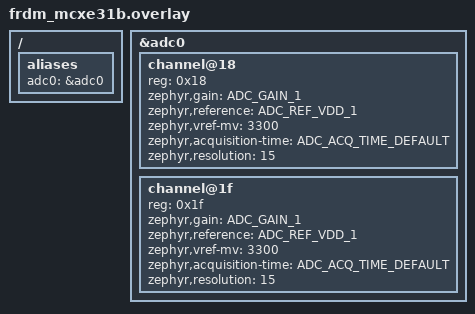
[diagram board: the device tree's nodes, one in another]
/*
 * Copyright 2025 NXP
 *
 * SPDX-License-Identifier: Apache-2.0
 */

#include <zephyr/dt-bindings/adc/adc.h>

/ {
	aliases {
		adc0 = &adc0;
	};
};

&adc0 {
	#address-cells = <1>;
	#size-cells = <0>;

	/* logic channel 24(0x18) => physical channel 48 (Internal 1.2v bandgap) */
	channel@18 {
		reg = <0x18>;
		zephyr,gain = "ADC_GAIN_1";
		zephyr,reference = "ADC_REF_VDD_1";
		zephyr,vref-mv = <3300>;
		zephyr,acquisition-time = <ADC_ACQ_TIME_DEFAULT>;
		zephyr,resolution = <15>;
	};

	/* logic channel 31(0x1F) => physical channel 55 (VREFH 3.3v) */
	channel@1f {
		reg = <0x1f>;
		zephyr,gain = "ADC_GAIN_1";
		zephyr,reference = "ADC_REF_VDD_1";
		zephyr,vref-mv = <3300>;
		zephyr,acquisition-time = <ADC_ACQ_TIME_DEFAULT>;
		zephyr,resolution = <15>;
	};
};
